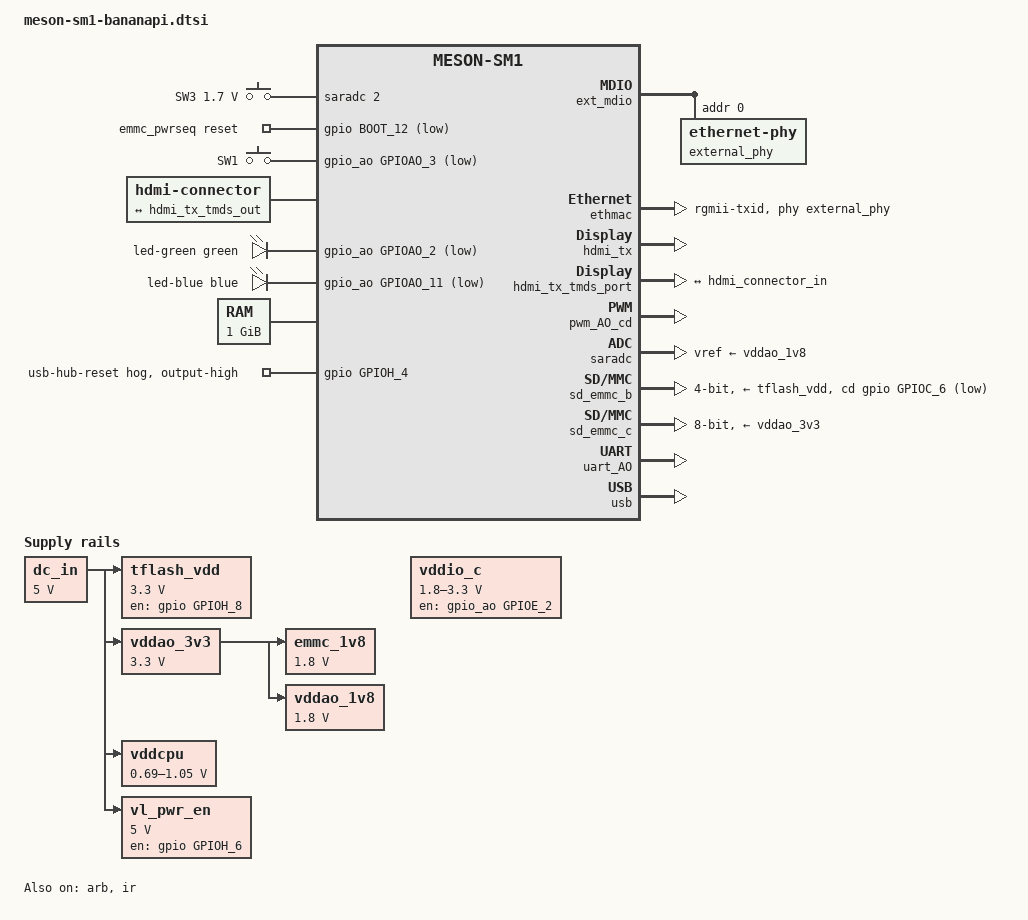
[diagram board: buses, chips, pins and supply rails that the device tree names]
#include "meson-sm1.dtsi"
#include <dt-bindings/leds/common.h>
#include <dt-bindings/input/linux-event-codes.h>
#include <dt-bindings/gpio/meson-g12a-gpio.h>
/ {
	adc-keys {
		compatible = "adc-keys";
		io-channels = <&saradc 2>;
		io-channel-names = "buttons";
		keyup-threshold-microvolt = <1800000>;
		button-sw3 {
			label = "SW3";
			linux,code = <BTN_3>;
			press-threshold-microvolt = <1700000>;
		};
	};
	aliases {
		serial0 = &uart_AO;
		ethernet0 = &ethmac;
	};
	chosen {
		stdout-path = "serial0:115200n8";
	};
	emmc_pwrseq: emmc-pwrseq {
		compatible = "mmc-pwrseq-emmc";
		reset-gpios = <&gpio BOOT_12 GPIO_ACTIVE_LOW>;
	};
	gpio-keys {
		compatible = "gpio-keys";
		key {
			label = "SW1";
			linux,code = <BTN_1>;
			gpios = <&gpio_ao GPIOAO_3 GPIO_ACTIVE_LOW>;
			interrupt-parent = <&gpio_intc>;
			interrupts = <IRQID_GPIOAO_3 IRQ_TYPE_EDGE_BOTH>;
		};
	};
	hdmi-connector {
		compatible = "hdmi-connector";
		type = "a";
		port {
			hdmi_connector_in: endpoint {
				remote-endpoint = <&hdmi_tx_tmds_out>;
			};
		};
	};
	leds {
		compatible = "gpio-leds";
		led-green {
			color = <LED_COLOR_ID_GREEN>;
			function = LED_FUNCTION_STATUS;
			gpios = <&gpio_ao GPIOAO_2 GPIO_ACTIVE_LOW>;
		};
		led-blue {
			color = <LED_COLOR_ID_BLUE>;
			function = LED_FUNCTION_STATUS;
			gpios = <&gpio_ao GPIOAO_11 GPIO_ACTIVE_LOW>;
			linux,default-trigger = "heartbeat";
		};
	};
	memory@0 {
		device_type = "memory";
		reg = <0x0 0x0 0x0 0x40000000>;
	};
	emmc_1v8: regulator-emmc_1v8 {
		compatible = "regulator-fixed";
		regulator-name = "EMMC_1V8";
		regulator-min-microvolt = <1800000>;
		regulator-max-microvolt = <1800000>;
		vin-supply = <&vddao_3v3>;
		regulator-always-on;
	};
	dc_in: regulator-dc_in {
		compatible = "regulator-fixed";
		regulator-name = "DC_IN";
		regulator-min-microvolt = <5000000>;
		regulator-max-microvolt = <5000000>;
		regulator-always-on;
	};
	vddio_c: regulator-vddio_c {
		compatible = "regulator-gpio";
		regulator-name = "VDDIO_C";
		regulator-min-microvolt = <1800000>;
		regulator-max-microvolt = <3300000>;
		enable-gpios = <&gpio_ao GPIOE_2 GPIO_OPEN_DRAIN>;
		enable-active-high;
		regulator-always-on;
		gpios = <&gpio_ao GPIOAO_6 GPIO_OPEN_DRAIN>;
		gpios-states = <1>;
		states = <1800000 0>,
			 <3300000 1>;
	};
	tflash_vdd: regulator-tflash_vdd {
		compatible = "regulator-fixed";
		regulator-name = "TFLASH_VDD";
		regulator-min-microvolt = <3300000>;
		regulator-max-microvolt = <3300000>;
		vin-supply = <&dc_in>;
		gpio = <&gpio GPIOH_8 GPIO_OPEN_DRAIN>;
		enable-active-high;
		regulator-always-on;
	};
	vddao_1v8: regulator-vddao_1v8 {
		compatible = "regulator-fixed";
		regulator-name = "VDDAO_1V8";
		regulator-min-microvolt = <1800000>;
		regulator-max-microvolt = <1800000>;
		vin-supply = <&vddao_3v3>;
		regulator-always-on;
	};
	vddao_3v3: regulator-vddao_3v3 {
		compatible = "regulator-fixed";
		regulator-name = "VDDAO_3V3";
		regulator-min-microvolt = <3300000>;
		regulator-max-microvolt = <3300000>;
		vin-supply = <&dc_in>;
		regulator-always-on;
	};
	vddcpu: regulator-vddcpu {
		compatible = "pwm-regulator";
		regulator-name = "VDDCPU";
		regulator-min-microvolt = <690000>;
		regulator-max-microvolt = <1050000>;
		pwm-supply = <&dc_in>;
		pwms = <&pwm_AO_cd 1 1250 0>;
		pwm-dutycycle-range = <100 0>;
		regulator-boot-on;
		regulator-always-on;
	};
	vl_pwr_en: regulator-vl_pwr_en {
		compatible = "regulator-fixed";
		regulator-name = "VL_PWR_EN";
		regulator-min-microvolt = <5000000>;
		regulator-max-microvolt = <5000000>;
		vin-supply = <&dc_in>;
		gpio = <&gpio GPIOH_6 GPIO_ACTIVE_HIGH>;
		enable-active-high;
	};
};
&arb {
	status = "okay";
};
&cpu0 {
	cpu-supply = <&vddcpu>;
	operating-points-v2 = <&cpu_opp_table>;
	clocks = <&clkc CLKID_CPU_CLK>;
	clock-latency = <50000>;
};
&cpu1 {
	cpu-supply = <&vddcpu>;
	operating-points-v2 = <&cpu_opp_table>;
	clocks = <&clkc CLKID_CPU1_CLK>;
	clock-latency = <50000>;
};
&cpu2 {
	cpu-supply = <&vddcpu>;
	operating-points-v2 = <&cpu_opp_table>;
	clocks = <&clkc CLKID_CPU2_CLK>;
	clock-latency = <50000>;
};
&cpu3 {
	cpu-supply = <&vddcpu>;
	operating-points-v2 = <&cpu_opp_table>;
	clocks = <&clkc CLKID_CPU3_CLK>;
	clock-latency = <50000>;
};
&ext_mdio {
	external_phy: ethernet-phy@0 {
		reg = <0>;
		max-speed = <1000>;
		interrupt-parent = <&gpio_intc>;
		interrupts = <IRQID_GPIOZ_14 IRQ_TYPE_LEVEL_LOW>;
	};
};
&ethmac {
	pinctrl-0 = <&eth_pins>, <&eth_rgmii_pins>;
	pinctrl-names = "default";
	status = "okay";
	phy-mode = "rgmii-txid";
	phy-handle = <&external_phy>;
};
&gpio {
	gpio-line-names =
		"ETH_MDIO",  
		"ETH_MDC",  
		"ETH_RXCLK",  
		"ETH_RX_DV",  
		"ETH_RXD0",  
		"ETH_RXD1",  
		"ETH_RXD2",  
		"ETH_RXD3",  
		"ETH_TXCLK",  
		"ETH_TXEN",  
		"ETH_TXD0",  
		"ETH_TXD1",  
		"ETH_TXD2",  
		"ETH_TXD3",  
		"ETH_INTR",  
		"ETH_NRST",  
		"HDMI_SDA",  
		"HDMI_SCL",  
		"HDMI_HPD",  
		"HDMI_CEC",  
		"VL-RST_N",  
		"CON1-P36",  
		"VL-PWREN",  
		"WiFi_3V3_1V8",  
		"TFLASH_VDD_EN",  
		"eMMC_D0",  
		"eMMC_D1",  
		"eMMC_D2",  
		"eMMC_D3",  
		"eMMC_D4",  
		"eMMC_D5",  
		"eMMC_D6",  
		"eMMC_D7",  
		"eMMC_CLK",  
		"",
		"eMMC_CMD",  
		"",
		"eMMC_RST#",  
		"eMMC_DS",  
		"", "",
		"SD_D0_B",  
		"SD_D1_B",  
		"SD_D2_B",  
		"SD_D3_B",  
		"SD_CLK_B",  
		"SD_CMD_B",  
		"CARD_EN_DET",  
		"",
		"", "", "", "", "", "", "", "",
		"", "", "", "", "", "",
		"CON1-P27",  
		"CON1-P28",  
		"CON1-P16",  
		"CON1-P18",  
		"CON1-P22",  
		"CON1-P11",  
		"CON1-P13",  
		"CON1-P07",  
		"CON1-P33",  
		"CON1-P15",  
		"CON1-P19",  
		"CON1-P21",  
		"CON1-P24",  
		"CON1-P23",  
		"CON1-P08",  
		"CON1-P10",  
		"CON1-P29",  
		"CON1-P31",  
		"CON1-P26",  
		"CON1-P03",  
		"CON1-P05",  
		"CON1-P32";  
	usb-hub-hog {
		gpio-hog;
		gpios = <GPIOH_4 GPIO_ACTIVE_HIGH>;
		output-high;
		line-name = "usb-hub-reset";
	};
};
&gpio_ao {
	gpio-line-names =
		"DEBUG TX",  
		"DEBUG RX",  
		"SYS_LED2",  
		"UPDATE_KEY",  
		"CON1-P40",  
		"IR_IN",  
		"TF_3V3N_1V8_EN",  
		"CON1-P35",  
		"CON1-P12",  
		"CON1-P37",  
		"CON1-P38",  
		"SYS_LED",  
		"VDDEE_PWM",  
		"VDDCPU_PWM",  
		"TF_PWR_EN";  
};
&hdmi_tx {
	status = "okay";
	pinctrl-0 = <&hdmitx_hpd_pins>, <&hdmitx_ddc_pins>;
	pinctrl-names = "default";
	hdmi-supply = <&dc_in>;
};
&hdmi_tx_tmds_port {
	hdmi_tx_tmds_out: endpoint {
		remote-endpoint = <&hdmi_connector_in>;
	};
};
&ir {
	status = "okay";
	pinctrl-0 = <&remote_input_ao_pins>;
	pinctrl-names = "default";
};
&pwm_AO_cd {
	pinctrl-0 = <&pwm_ao_d_e_pins>;
	pinctrl-names = "default";
	clocks = <&xtal>;
	clock-names = "clkin1";
	status = "okay";
};
&saradc {
	status = "okay";
	vref-supply = <&vddao_1v8>;
};
&sd_emmc_b {
	status = "okay";
	pinctrl-0 = <&sdcard_c_pins>;
	pinctrl-1 = <&sdcard_clk_gate_c_pins>;
	pinctrl-names = "default", "clk-gate";
	bus-width = <4>;
	cap-sd-highspeed;
	max-frequency = <50000000>;
	disable-wp;
	cd-gpios = <&gpio GPIOC_6 GPIO_ACTIVE_LOW>;
	vmmc-supply = <&tflash_vdd>;
	vqmmc-supply = <&vddio_c>;
};
&sd_emmc_c {
	status = "okay";
	pinctrl-0 = <&emmc_ctrl_pins>, <&emmc_data_8b_pins>, <&emmc_ds_pins>;
	pinctrl-1 = <&emmc_clk_gate_pins>;
	pinctrl-names = "default", "clk-gate";
	bus-width = <8>;
	cap-mmc-highspeed;
	mmc-ddr-1_8v;
	mmc-hs200-1_8v;
	max-frequency = <200000000>;
	disable-wp;
	mmc-pwrseq = <&emmc_pwrseq>;
	vmmc-supply = <&vddao_3v3>;
	vqmmc-supply = <&emmc_1v8>;
};
&uart_AO {
	status = "okay";
	pinctrl-0 = <&uart_ao_a_pins>;
	pinctrl-names = "default";
};
&usb {
	status = "okay";
};
&usb2_phy0 {
	phy-supply = <&dc_in>;
};
&usb2_phy1 {
	phy-supply = <&vl_pwr_en>;
};
